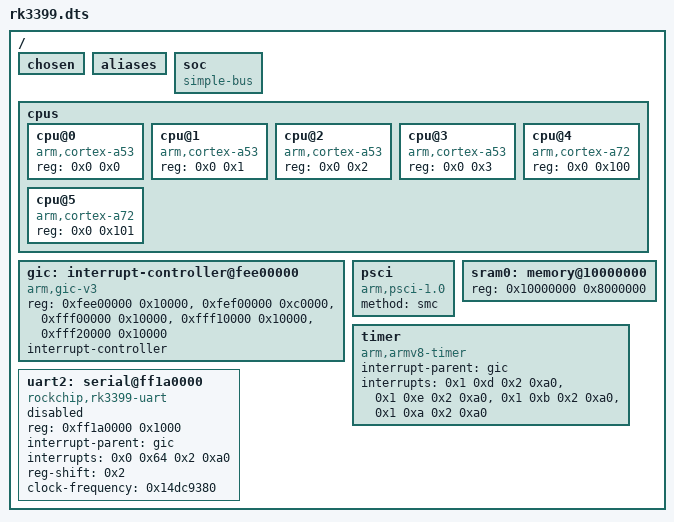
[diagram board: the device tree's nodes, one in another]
/dts-v1/;

/ {
	#address-cells = < 0x1 >;
	#size-cells = < 0x1 >;
	chosen {
	};
	aliases {
	};
	soc {
		#address-cells = < 0x1 >;
		#size-cells = < 0x1 >;
		compatible = "simple-bus";
		ranges;
	};
	cpus {
		#address-cells = < 0x2 >;
		#size-cells = < 0x0 >;
		cpu@0 {
			device_type = "cpu";
			compatible = "arm,cortex-a53";
			reg = < 0x0 0x0 >;
		};
		cpu@1 {
			device_type = "cpu";
			compatible = "arm,cortex-a53";
			reg = < 0x0 0x1 >;
		};
		cpu@2 {
			device_type = "cpu";
			compatible = "arm,cortex-a53";
			reg = < 0x0 0x2 >;
		};
		cpu@3 {
			device_type = "cpu";
			compatible = "arm,cortex-a53";
			reg = < 0x0 0x3 >;
		};
		cpu@4 {
			device_type = "cpu";
			compatible = "arm,cortex-a72";
			reg = < 0x0 0x100 >;
		};
		cpu@5 {
			device_type = "cpu";
			compatible = "arm,cortex-a72";
			reg = < 0x0 0x101 >;
		};
	};
	gic: interrupt-controller@fee00000 {
		#address-cells = < 0x1 >;
		compatible = "arm,gic-v3", "arm,gic";
		reg = < 0xfee00000 0x10000 >, < 0xfef00000 0xc0000 >, < 0xfff00000 0x10000 >, < 0xfff10000 0x10000 >, < 0xfff20000 0x10000 >;
		interrupt-controller;
		#interrupt-cells = < 0x4 >;
		status = "okay";
		phandle = < 0x1 >;
	};
	psci: psci {
		compatible = "arm,psci-1.0";
		method = "smc";
	};
	sram0: memory@10000000 {
		reg = < 0x10000000 0x8000000 >;
	};
	timer {
		compatible = "arm,armv8-timer";
		interrupt-parent = < &gic >;
		interrupts = < 0x1 0xd 0x2 0xa0 >, < 0x1 0xe 0x2 0xa0 >, < 0x1 0xb 0x2 0xa0 >, < 0x1 0xa 0x2 0xa0 >;
	};
	uart2: serial@ff1a0000 {
		compatible = "rockchip,rk3399-uart", "ns16550";
		reg = < 0xff1a0000 0x1000 >;
		interrupt-parent = < &gic >;
		interrupts = < 0x0 0x64 0x2 0xa0 >;
		status = "disabled";
		reg-shift = < 0x2 >;
		clock-frequency = < 0x14dc9380 >;
	};
};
